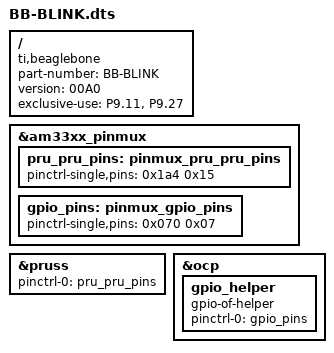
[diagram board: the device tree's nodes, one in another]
/dts-v1/;
/plugin/;
/{
	compatible = "ti,beaglebone", "ti,beaglebone-black", "ti,beaglebone-green";
	part-number = "BB-BLINK";
	version = "00A0";

	exclusive-use = "P9.11", "P9.27";

	fragment@0 {
		target = <&am33xx_pinmux>;
		__overlay__ {			
			pru_pru_pins: pinmux_pru_pru_pins {		// The PRU pin modes
				pinctrl-single,pins = <
					0x1a4 0x15  // P9_27 pr1_pru0_pru_r30_5, MODE5 | OUTPUT | PULL_DOWN
				>;
			};
			gpio_pins: pinmux_gpio_pins {
				pinctrl-single,pins = <
					0x070 0x07 // P9_11 GPIO MODE7 | OUTPUT | PULL_DOWN
				>;
			};
		};
	};
	
	fragment@1{		// Enable the PRUSS
		target = <&pruss>;
		__overlay__ {
			status = "okay";
			pinctrl-names = "default";
			pinctrl-0 = <&pru_pru_pins>;
		};
	};

	fragment@2{		// Enable the GPIOs
		target = <&ocp>;
		__overlay__ {
			gpio_helper {
				compatible = "gpio-of-helper";
				status = "okay";
				pinctrl-names = "default";
				pinctrl-0 = <&gpio_pins>;
			};
		};
	};
};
